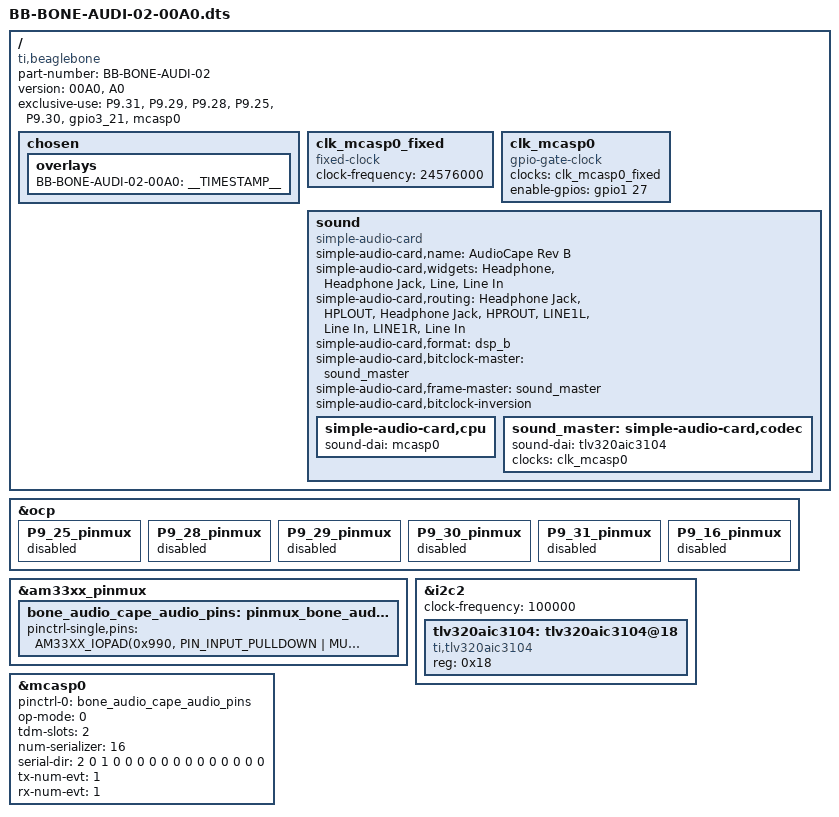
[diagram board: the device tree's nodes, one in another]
/*
 * Copyright (C) 2012 Texas Instruments Incorporated - http://www.ti.com/
 *
 * This program is free software; you can redistribute it and/or modify
 * it under the terms of the GNU General Public License version 2 as
 * published by the Free Software Foundation.
 */

/dts-v1/;
/plugin/;

#include <dt-bindings/gpio/gpio.h>
#include <dt-bindings/pinctrl/am33xx.h>

/ {
	compatible = "ti,beaglebone", "ti,beaglebone-black", "ti,beaglebone-green";

	/* identification */
	part-number = "BB-BONE-AUDI-02";
	version = "00A0", "A0";

	/* state the resources this cape uses */
	exclusive-use =
		/* the pin header uses */
		"P9.31",	/* mcasp0: mcasp0_aclkx */
		"P9.29",	/* mcasp0: mcasp0_fsx */
		"P9.28",	/* mcasp0: mcasp0_axr2 */
		"P9.25",	/* mcasp0: mcasp0_ahclkx */
		"P9.30",	/* mcasp0: mcasp0_axr0 */
		/* the hardware ip uses */
		"gpio3_21",
		"mcasp0";

	/*
	 * Helper to show loaded overlays under: /proc/device-tree/chosen/overlays/
	 */
	fragment@0 {
		target-path="/";
		__overlay__ {

			chosen {
				overlays {
					BB-BONE-AUDI-02-00A0 = __TIMESTAMP__;
				};
			};
		};
	};

	/*
	 * Free up the pins used by the cape from the pinmux helpers.
	 */
	fragment@1 {
		target = <&ocp>;
		__overlay__ {
			P9_25_pinmux { status = "disabled"; };	/* mcasp0_ahclkx */
			P9_28_pinmux { status = "disabled"; };	/* mcasp0_axr2 */
			P9_29_pinmux { status = "disabled"; };	/* mcasp0_fsx */
			P9_30_pinmux { status = "disabled"; };	/* mcasp0_axr0 */
			P9_31_pinmux { status = "disabled"; };	/* mcasp0_aclkx */
			P9_16_pinmux { status = "disabled"; };
		};
	};

	fragment@2 {
		target = <&am33xx_pinmux>;
		__overlay__ {
			bone_audio_cape_audio_pins: pinmux_bone_audio_cape_audio_pins {
				pinctrl-single,pins = <
					AM33XX_IOPAD(0x990, PIN_INPUT_PULLDOWN | MUX_MODE0)	/* mcasp0_aclkx.mcasp0_aclkx */
					AM33XX_IOPAD(0x994, PIN_INPUT_PULLDOWN | MUX_MODE0)	/* mcasp0_fsx.mcasp0_fsx, INPUT */
					AM33XX_IOPAD(0x998, PIN_INPUT_PULLDOWN | MUX_MODE0)	/* mcasp0_axr0.mcasp0_axr0 */
					AM33XX_IOPAD(0x99c, PIN_INPUT_PULLDOWN | MUX_MODE2)	/* mcasp0_ahclkr.mcasp0_axr2 */
					AM33XX_IOPAD(0x9ac, PIN_INPUT_PULLDOWN | MUX_MODE0)	/* MCASP0_AHCLKX -> MCASP0_AHCLKX (I2S_MCLK_OUT)- in */
					AM33XX_IOPAD(0x86c, PIN_OUTPUT_PULLDOWN | MUX_MODE7)	/* gpmc_a11.GPIO1_27 */
					AM33XX_IOPAD(0x84c, PIN_OUTPUT_PULLUP | MUX_MODE7)	/* gpmc_a11.GPIO1_19 */
				>;
			};
		};
	};

	fragment@3 {
		target-path="/";
		__overlay__ {
			clk_mcasp0_fixed: clk_mcasp0_fixed {
				#clock-cells = <0>;
				compatible = "fixed-clock";
				clock-frequency = <24576000>;
			};

			clk_mcasp0: clk_mcasp0 {
				#clock-cells = <0>;
				compatible = "gpio-gate-clock";
				clocks = <&clk_mcasp0_fixed>;
				enable-gpios = <&gpio1 27 0>; /* BeagleBone Black Clk enable on GPIO1_27 */
			};

			sound {
				compatible = "simple-audio-card";
				simple-audio-card,name = "AudioCape Rev B";
				simple-audio-card,widgets =
					"Headphone", "Headphone Jack",
					"Line", "Line In";
				simple-audio-card,routing =
					"Headphone Jack",       "HPLOUT",
					"Headphone Jack",       "HPROUT",
					"LINE1L",               "Line In",
					"LINE1R",               "Line In";
				simple-audio-card,format = "dsp_b";
				simple-audio-card,bitclock-master = <&sound_master>;
				simple-audio-card,frame-master = <&sound_master>;
				simple-audio-card,bitclock-inversion;

				simple-audio-card,cpu {
					sound-dai = <&mcasp0>;
				};

				sound_master: simple-audio-card,codec {
					#sound-dai-cells = <0>;
					sound-dai = <&tlv320aic3104>;
					clocks = <&clk_mcasp0>;
					clock-names = "mclk";
				};
			};
		};
	};

	fragment@4 {
		target = <&i2c2>;
		__overlay__ {
			#address-cells = <1>;
			#size-cells = <0>;
			clock-frequency = <100000>;
			status = "okay";

			tlv320aic3104: tlv320aic3104@18 {
				#sound-dai-cells = <0>;
				compatible = "ti,tlv320aic3104";
				reg = <0x18>;
			};
		};
	};

	fragment@5 {
		target = <&mcasp0>;
		__overlay__ {
			#sound-dai-cells = <0>;
			pinctrl-names = "default";
			pinctrl-0 = <&bone_audio_cape_audio_pins>;
			status = "okay";
			op-mode = <0>;	/* MCASP_IIS_MODE */
			tdm-slots = <2>;
			num-serializer = <16>;
			serial-dir = <	/* 0: INACTIVE, 1: TX, 2: RX */
					2 0 1 0
					0 0 0 0
					0 0 0 0
					0 0 0 0
				>;
			tx-num-evt = <1>;
			rx-num-evt = <1>;
		};
	};
};
